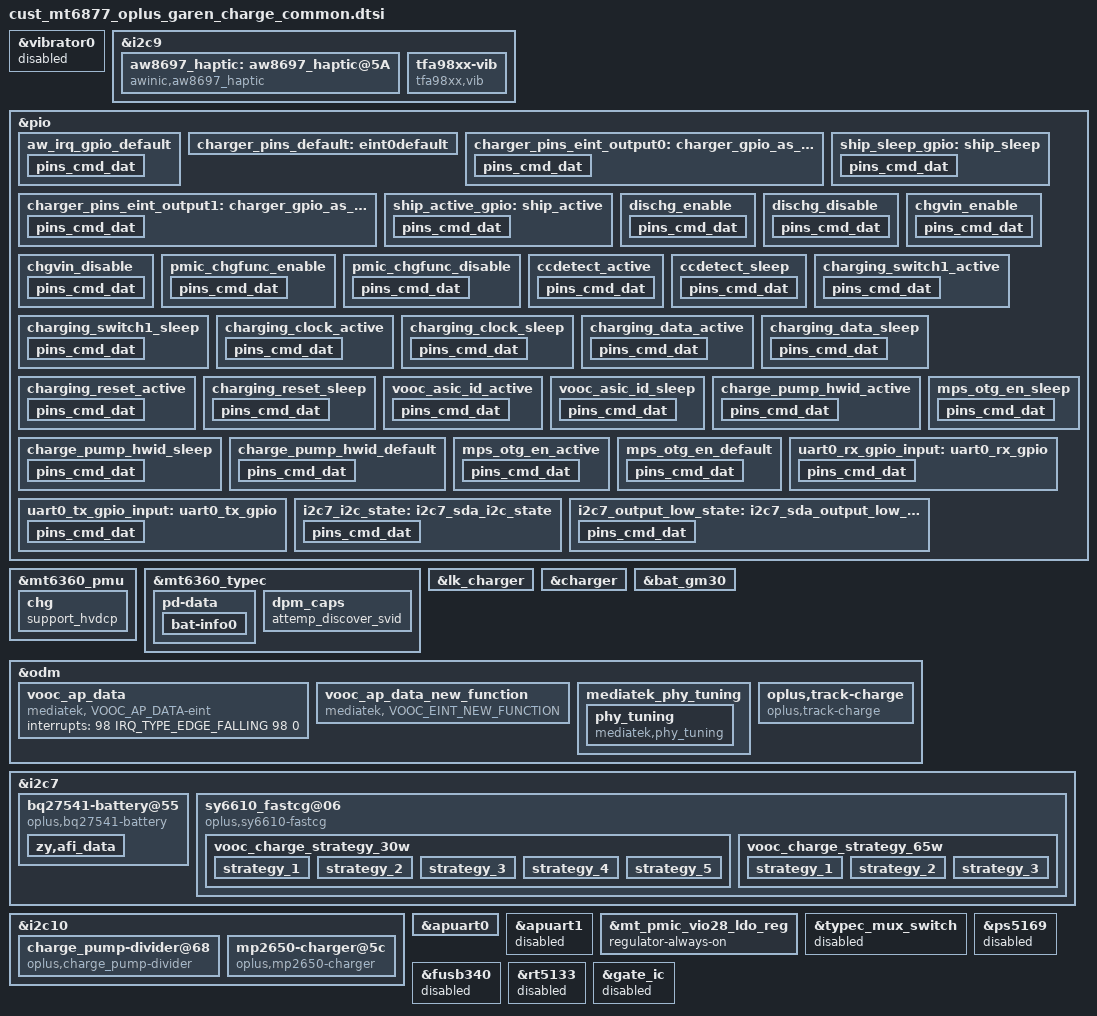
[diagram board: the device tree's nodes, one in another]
// SPDX-License-Identifier: GPL-2.0-only
/*
* Copyright (C) 2020-2021 Oplus. All rights reserved.
*/

//#ifdef OPLUS_FEATURE_CHG_BASIC
/*
 *
 * CPU:				--> MT6877
 * GPIO:
 * AP_AW			--> GPIO117(20181 EVT+20355 T0 NC)
 * LRA_RST			--> GPIO118(20181 EVT+20355 T0 I2S1_BCLK_SMPA)
 * AW_INT			--> GPIO3(20181 EVT+20355 T0 NC)
 * NDT_AW_SCL			--> GPIO147(SCL9)
 * NDT_AW_SDA			--> GPIO148(SDA9)
 *
 * MT6360_CHG_EN		--> GPIO111
 * PERIEN_CHG_ENB		--> GPIO142
 * MT6360_SCL			--> GPIO132(SCL5)
 * MT6360_SDA			--> GPIO133(SDA5)
 * EINT_SUBPMIC_IRQB		--> GPIO4
 * EINT_SUBPMIC_PD_IRQB		--> GPIO5
 *
 * GAUGE_SCL			--> GPIO134(SCL7)
 * GAUGE_SDA			--> GPIO135(SDA7)
 * AP_CLK			--> GPIO180
 * AP_DATA			--> GPIO181
 * SW_CTRL			--> GPIO24
 * USB_ON			--> GPIO25(20181 EVB-GPIO26 PU)
 * MCU_EN			--> GPIO33
 * ASIC_ID			--> GPIO34
 * ASIC_INT			--> GPIO9
 * SHIP_MODE_ON			--> GPIO108
 * UTXD0			--> GPIO178
 * URXD0			--> GPIO179
 *
 * MP2762_DA9313_SCL		--> GPIO191(SCL10)
 * MP2762_DA9313_SDA		--> GPIO192(SDA10)
 * MPS_OTG_EN			--> GPIO107
 * INPUT_PG			--> GPIO29
 * ChargerPump_ID		--> GPIO30
 * MAX77932_IRQB		--> GPIO10
 *
 * USB_ACC_INT			--> GPIO6
 * VBUS_SHORT			--> GPIO167(VIO28)
 *
 * AUXADC:
 * 0				--> AUX_IN0_NTC_AP
 * 1				--> AUX_IN1_NTC_PA1
 * 2				--> AUX_IN2_NTC_PA2
 * 3				--> CAM_FLASH_THER
 * 4				--> AUX_IN4_NTC_USB
 * 5				--> AUX_IN5_NTC_USB
 * 6				--> CHG_MOS_THERM
 * 7				--> MAIN_BOARD_ID
 * 8				--> SUB_BOARD_ID
 *******************************************
 * main pmic:			--> MT6365
 * charge pmic:			--> MT6360
 * charge ic:			--> MP2762GV
 * asic ic:
 * PD				--> SY6610(USE)
 * HZ				--> RT5125
 * PU				--> RK826
 * charge pump ic:
 * PD				--> DA9313/SD77313
 * PU				--> MAX77932/MAX77938
 * haptic ic:			--> AW8697/TFA9873
 * gauge ic:			--> sn28z719/SH366003
 * linear motor:		--> DM-LM0832-67
 */

&vibrator0 {
	status = "disabled";
};

&i2c9 {
	status = "okay";
	scl-gpio-id = <147>;
	sda-gpio-id = <148>;

	/* AWINIC AW8697 Haptic */
	aw8697_haptic: aw8697_haptic@5A {
		status = "okay";
		compatible = "awinic,aw8697_haptic";
		reg = <0x5A>;
		reset-gpio = <&pio 118 0x00>;
		irq-gpio = <&pio 3 0x00>;
		qcom,device_id = <832>;

		pinctrl-names = "default";
		pinctrl-0 = <&aw_irq_gpio_default>;
	};

	/*add for lk vib*/
	tfa98xx-vib {
		status = "okay";
		compatible = "tfa98xx,vib";
		reset-gpio =  <32>;
		interval_time = <14000>;
	};
};

&pio{
	aw_irq_gpio_default: aw_irq_gpio_default {
		pins_cmd_dat {
			pinmux = <PINMUX_GPIO3__FUNC_GPIO3>;
			input-enable;
			slew-rate = <0>;
			bias-pull-up;
		};
	};
};

&mt6360_pmu {
	mt6360,intr_gpio_num = <4>; /* direct defined GPIO num */
	mt6360,intr_gpio = <&pio 4 0x0>;
	disable_lpsd = <1>;

	chg {
		support_hvdcp;
	};
};

&mt6360_typec {
	mt6360pd,intr_gpio_num = <5>; /* direct defined GPIO num */
	mt6360pd,intr_gpio = <&pio 5 0x0>;
	mt-tcpc,role_def = <1>; /* 0: Unknown, 1: SNK only, 2: SRC only, 3: DRP, 4: Try.SRC, 5: Try.SNK */
	mt-tcpc,vconn_supply  = <1>; /* 0: Never, 1: Always, 2: EMarkOnly, 3: StartOnly */
	pd-data {
		pd,source-pdo-size = <1>;
		pd,source-pdo-data = <0x00019096>; /* Fixed5V1.5A */

		pd,sink-pdo-size = <2>;
		pd,sink-pdo-data = <0x000190c8 0x0001912c>; /* Fixed5V2A Fixed5V3A */

		pd,id-vdo-size = <3>;
		pd,id-vdo-data = <0xd10029cf 0x0 0x63600000>; /* No DP, host + device */

		bat,nr = <1>;
		bat-info0 {
			bat,vid = <0x29cf>;
			bat,pid = <0x6360>;
			bat,mfrs = "bat1";
			bat,design_cap = <16>; /*7.74V*2.15Ah=16.254Wh*/
		};
	};

	dpm_caps {
		attemp_discover_svid;
	};
};

&lk_charger{
	charger_by_buckboost;
	support_tuv_authentication;
};

&charger {
	io-channels = <&auxadc 4>,
		<&auxadc 5>,
		<&auxadc 6>;
	io-channel-names = "auxadc4-usb_temp_v_l",
		"auxadc5-usb_temp_v_r",
		"auxadc3-chargeric_temp";

	pinctrl-names = "default", "charger_gpio_as_output_low", "charger_gpio_as_output_high", "ship_sleep", "ship_active",
		"dischg_enable", "dischg_disable", "chgvin_enable", "chgvin_disable", "pmic_chgfunc_enable", "pmic_chgfunc_disable",
		"ccdetect_active","ccdetect_sleep";
	pinctrl-0 = <&charger_pins_default>;
	pinctrl-1 = <&charger_pins_eint_output0>;
	pinctrl-2 = <&charger_pins_eint_output1>;
	pinctrl-3 = <&ship_sleep_gpio>;
	pinctrl-4 = <&ship_active_gpio>;
	pinctrl-5 = <&dischg_enable>;
	pinctrl-6 = <&dischg_disable>;
	pinctrl-7 = <&chgvin_enable>;
	pinctrl-8 = <&chgvin_disable>;
	pinctrl-9 = <&pmic_chgfunc_enable>;
	pinctrl-10 = <&pmic_chgfunc_disable>;
	pinctrl-11 = <&ccdetect_active>;
	pinctrl-12 = <&ccdetect_sleep>;

	qcom,hv_flashled_support;
	qcom,chargerid_support;
	qcom,smart_charging_screenoff;
	qcom,usbtemp_batttemp_gap = <18>;
	qcom,input_current_charger_ma = <2000>;
	qcom,pd_input_current_charger_ma = <2000>;
	qcom,qc_input_current_charger_ma = <2000>;
	qcom,input_current_usb_ma = <500>;

	qcom,input_current_led_ma = <1200>;
	qcom,input_current_led_ma_high = <1200>;
	qcom,input_current_led_ma_warm = <1500>;
	qcom,input_current_led_ma_normal = <2000>;
	qcom,led_warm_bat_decidegc = <350>;
	qcom,led_high_bat_decidegc = <370>;

	qcom,input_current_camera_ma = <1200>;
	qcom,input_current_cdp_ma = <1500>;

	qcom,input_current_vooc_led_ma_high = <1200>;
	qcom,input_current_vooc_led_ma_warm = <1800>;
	qcom,input_current_vooc_led_ma_normal = <3600>;
	qcom,input_current_vooc_ma_normal = <3600>;
	qcom,vooc_temp_bat_normal_decidegc = <350>;
	qcom,input_current_vooc_ma_warm = <3200>;
	qcom,vooc_temp_bat_warm_decidegc = <370>;
	qcom,input_current_vooc_ma_high = <2200>;
	qcom,vooc_temp_bat_hot_decidegc = <440>;

	qcom,charger_current_vooc_ma_normal = <1800>;

	qcom,chg_ctrl_by_calling;
	qcom,input_current_calling_ma = <1500>;

	qcom,overtemp_bat_decidegc = <350>;
	qcom,iterm_disabled = <0>;
	sw_full_count = <25>;
	qcom,iterm_ma = <115>;
	qcom,recharge-mv = <100>;
	qcom,batt_capacity_mah = <4300>;/*typical capacity*/

	qcom,removed_bat_decidegc = <190>;  /*<-19C*/

	qcom,cold_bat_decidegc = <20>;  /*-2C~0C*/
	qcom,temp_cold_vfloat_mv = <3980>;
	qcom,temp_cold_fastchg_current_ma = <300>;

	qcom,little_cold_bat_decidegc = <0>;    /*0C~5C*/
	qcom,temp_little_cold_vfloat_mv = <4435>;
	qcom,temp_little_cold_fastchg_current_ma_high = <1100>;
	qcom,temp_little_cold_fastchg_current_ma_low = <1100>;
	qcom,temp_little_cold_fastchg_current_ma = <1100>;
	qcom,pd_temp_little_cold_fastchg_current_ma_high = <1950>;
	qcom,pd_temp_little_cold_fastchg_current_ma_low = <1350>;
	qcom,qc_temp_little_cold_fastchg_current_ma_high = <1950>;
	qcom,qc_temp_little_cold_fastchg_current_ma_low = <1350>;

	qcom,cool_bat_decidegc = <50>;  /*5C~12C*/
	qcom,temp_cool_vfloat_mv = <4435>;
	qcom,temp_cool_fastchg_current_ma_high = <1100>;
	qcom,temp_cool_fastchg_current_ma_low = <1100>;
	qcom,pd_temp_cool_fastchg_current_ma_high = <2000>;
	qcom,pd_temp_cool_fastchg_current_ma_low = <2000>;
	qcom,qc_temp_cool_fastchg_current_ma_high = <2000>;
	qcom,qc_temp_cool_fastchg_current_ma_low = <2000>;

	qcom,little_cool_bat_decidegc = <120>;  /*12C~16C*/
	qcom,temp_little_cool_vfloat_mv = <4435>;
	qcom,temp_little_cool_fastchg_current_ma = <1100>;
	qcom,pd_temp_little_cool_fastchg_current_ma = <2000>;
	qcom,qc_temp_little_cool_fastchg_current_ma = <2000>;

	qcom,normal_bat_decidegc = <160>;       /*16C~45C*/
	qcom,temp_normal_vfloat_mv = <4435>;
	qcom,temp_normal_fastchg_current_ma = <1100>;
	qcom,pd_temp_normal_fastchg_current_ma = <2000>;
	qcom,qc_temp_normal_fastchg_current_ma = <2000>;

	qcom,warm_bat_decidegc = <450>;         /*45C~53C*/ /*8pin Bat Vooc project need add 3 degree C*/
	qcom,temp_warm_vfloat_mv = <4130>;
	qcom,temp_warm_fastchg_current_ma = <550>;
	qcom,pd_temp_warm_fastchg_current_ma = <550>;
	qcom,qc_temp_warm_fastchg_current_ma = <550>;
	qcom,temp_warm_fastchg_current_ma_led_on = <250>;

	qcom,hot_bat_decidegc = <530>;

	qcom,non_standard_vfloat_mv = <3980>;
	qcom,non_standard_fastchg_current_ma = <512>;

	qcom,short_c_bat_cv_mv = <4330>;
	qcom,short_c_bat_vfloat_mv = <3800>;
	qcom,short_c_bat_fastchg_current_ma = <512>;

	qcom,cold_vfloat_sw_limit = <3930>;
	qcom,little_cold_vfloat_sw_limit = <4385>;
	qcom,cool_vfloat_sw_limit = <4385>;
	qcom,little_cool_vfloat_sw_limit = <4385>;
	qcom,normal_vfloat_sw_limit = <4385>;
	qcom,warm_vfloat_sw_limit = <4080>;
	qcom,non_standard_vfloat_sw_limit = <3930>;
	qcom,short_c_bat_vfloat_sw_limit = <3750>;

	qcom,max_chg_time_sec = <61200>;
	qcom,charger_hv_thr = <9900>;
	qcom,charger_recv_thr = <9500>;
	qcom,charger_lv_thr = <3400>;
	qcom,vbatt_full_thr = <4435>;
	qcom,vbatt_hv_thr = <4600>;

	qcom,vfloat_step_mv = <8>;
	qcom,cold_vfloat_over_sw_limit = <3990>;
	qcom,little_cold_vfloat_over_sw_limit = <4445>;
	qcom,cool_vfloat_over_sw_limit = <4445>;
	qcom,little_cool_vfloat_over_sw_limit = <4445>;
	qcom,normal_vfloat_over_sw_limit = <4445>;
	qcom,warm_vfloat_over_sw_limit = <4140>;
	qcom,non_standard_vfloat_over_sw_limit = <3990>;

	qcom,vbatt_power_off = <3300>;
	qcom,vbatt_soc_1 = <3310>;
	qcom,vooc_project = <3>;
	qcom,vbatt_num = <2>;
	qcom,new_ui_warning_support;
	qcom,ffc_support;
	qcom,dual_ffc;
	recharge_after_full;

	qcom,normal_vterm_hw_inc = <18>;
	qcom,non_normal_vterm_hw_inc = <18>;

	qcom,ff1_normal_fastchg_ma = <550>;
	qcom,ff1_warm_fastchg_ma = <550>;

	qcom,ffc2_normal_fastchg_ma = <350>;/*12C~35c*/
	qcom,ffc2_temp_warm_decidegc = <350>;
	qcom,ffc2_warm_fastchg_ma = <350>;/*35C~40c*/
	qcom,ffc2_temp_high_decidegc = <400>;
	qcom,ffc2_temp_low_decidegc = <120>;

	qcom,ff1_exit_step_ma = <150>;
	qcom,ff1_warm_exit_step_ma = <150>;
	qcom,ffc2_exit_step_ma = <150>;
	qcom,ffc2_warm_exit_step_ma = <150>;

	qcom,ffc_normal_vfloat_sw_limit = <4445>;
	qcom,ffc_temp_normal_vfloat_mv = <4500>;
	qcom,ffc_normal_vfloat_over_sw_limit = <4500>;
	qcom,ffc_warm_vfloat_sw_limit = <4445>;
	qcom,ffc_temp_warm_vfloat_mv = <4500>;
	qcom,ffc_warm_vfloat_over_sw_limit = <4500>;

	qcom,ffc2_normal_vfloat_sw_limit = <4440>;
	qcom,ffc2_temp_normal_vfloat_mv = <4500>;
	qcom,ffc2_normal_vfloat_over_sw_limit = <4500>;
	qcom,ffc2_warm_vfloat_sw_limit = <4435>;
	qcom,ffc2_temp_warm_vfloat_mv = <4500>;
	qcom,ffc2_warm_vfloat_over_sw_limit = <4500>;

	qcom,default_iterm_ma = <115>;
	qcom,default_temp_normal_fastchg_current_ma = <1100>;
	qcom,default_normal_vfloat_sw_limit = <4385>;
	qcom,default_temp_normal_vfloat_mv = <4435>;
	qcom,default_normal_vfloat_over_sw_limit = <4445>;

	qcom,default_temp_little_cool_fastchg_current_ma = <1100>;
	qcom,default_little_cool_vfloat_sw_limit = <4385>;
	qcom,default_temp_little_cool_vfloat_mv = <4435>;
	qcom,default_little_cool_vfloat_over_sw_limit = <4445>;

	qcom,vooc_show_ui_soc_decimal;
	qcom,ui_soc_decimal_speedmin = <20>;//2A
	qcom,check_batt_full_by_sw;
	qcom,external_gauge;
	qcom,chg_ctrl_by_lcd;
	qcom,chg_ctrl_by_vooc;
	qcom,chg_ctrl_by_camera;
	qcom,support_ntc_01c_precision;
	qcom,sw_vfloat_over_protect_enable;

	qcom,support_abnormal_adapter;

	//for PD9V or QC9V
	qcom,vbatt_pdqc_to_5v_thr = <4100>;
	qcom,vbatt_pdqc_to_9v_thr = <4000>;

	oplus,aging_ffc_version = <1>;

	//GPIO config:
	qcom,chargerid_switch-gpio = <&pio 25 0x00>;
	qcom,ship-gpio = <&pio 108 0x00>;
	qcom,dischg-gpio = <&pio 167 0x00>;
	qcom,ccdetect-gpio = <&pio 6 0x00>;

	qcom,chgvin = <&pio 111 0x00>;
	qcom,pmic_chgfunc = <&pio 142 0x00>;
};

&pio {
	charger_pins_default: eint0default {
	};

	charger_pins_eint_output0: charger_gpio_as_output_low {
		pins_cmd_dat {
			pinmux = <PINMUX_GPIO25__FUNC_GPIO25>;
			slew-rate = <1>;
			output-low;
		};
	};

	charger_pins_eint_output1: charger_gpio_as_output_high {
		pins_cmd_dat {
			pinmux = <PINMUX_GPIO25__FUNC_GPIO25>;
			slew-rate = <1>;
			output-high;
		};
	};

	ship_sleep_gpio: ship_sleep {
		pins_cmd_dat {
			pinmux = <PINMUX_GPIO108__FUNC_GPIO108>;
			slew-rate = <1>;
			output-low;
		};
	};

	ship_active_gpio: ship_active {
		pins_cmd_dat {
			pinmux = <PINMUX_GPIO108__FUNC_GPIO108>;
			slew-rate = <1>;
			output-high;
		};
	};

	dischg_enable: dischg_enable {
		pins_cmd_dat {
			pinmux = <PINMUX_GPIO167__FUNC_GPIO167>;
			slew-rate = <1>;
			output-high;
		};
	};

	dischg_disable: dischg_disable {
		pins_cmd_dat {
			pinmux = <PINMUX_GPIO167__FUNC_GPIO167>;
			slew-rate = <1>;
			output-low;
		};
	};

	chgvin_enable: chgvin_enable {
		pins_cmd_dat {
			pinmux = <PINMUX_GPIO111__FUNC_GPIO111>;
			slew-rate = <1>;
			output-low;
		};
	};

	chgvin_disable: chgvin_disable {
		pins_cmd_dat {
			pinmux = <PINMUX_GPIO111__FUNC_GPIO111>;
			slew-rate = <1>;
			output-high;
		};
	};

	pmic_chgfunc_enable: pmic_chgfunc_enable {
		pins_cmd_dat {
			pinmux = <PINMUX_GPIO142__FUNC_GPIO142>;
			slew-rate = <1>;
			output-low;
		};
	};

	pmic_chgfunc_disable: pmic_chgfunc_disable {
		pins_cmd_dat {
			pinmux = <PINMUX_GPIO142__FUNC_GPIO142>;
			slew-rate = <1>;
			output-high;
		};
	};

	ccdetect_active: ccdetect_active {
		pins_cmd_dat {
			pinmux = <PINMUX_GPIO6__FUNC_GPIO6>;
			input-enable;
			slew-rate = <0>;
			bias-disable;
		};
	};

	ccdetect_sleep: ccdetect_sleep {
		pins_cmd_dat {
			pinmux = <PINMUX_GPIO6__FUNC_GPIO6>;
			input-enable;
			slew-rate = <0>;
			bias-disable;
		};
	};
};

&bat_gm30 {
	FUELGAGUE_APPLY = <(0)>;
	DISABLE_MTKBATTERY = <(1)>;
};

&odm {
	vooc_ap_data:vooc_ap_data {
		compatible = "mediatek, VOOC_AP_DATA-eint";
		interrupts = <98 IRQ_TYPE_EDGE_FALLING 98 0>;
	};

	vooc_ap_data_new_function:vooc_ap_data_new_function {
		compatible = "mediatek, VOOC_EINT_NEW_FUNCTION";
	};
};

&i2c7 {
	status = "okay";
	clock-frequency = <100000>;//100K
	scl-gpio-id = <134>;
	sda-gpio-id = <135>;

	bq27541-battery@55 {
		status = "okay";
		compatible = "oplus,bq27541-battery";
		reg = <0x55>;
		qcom,modify-soc-smooth;
		qcom,modify-soc-calibration;
		qcom,batt_bq28z610;
		qcom,sha1_key_index = <1>;
		//qcom,bq28z610_need_balancing;
		zy,afi_data{
			battery,name = "BLP863";
			qmax_min = <1696>;
			qmax_max = <2438>;
			static_df_checksum_3e = [79 C0];			//len 2
			static_df_checksum_60 = [0A 06];			//len 2
			afi_buf_num = <7>;
			afi_buf_0 = [
				11 D0 11 17 11 D0 11 17 11 D0 11 17 11 D0 11 17
				01 0A 8C 0A 0C 1C 21 34 02 FF CE 02 EC 78 02 FF
				CE 05 C2 0A C2 0A 72 A3 0A 0C D1 02 0C 9F 0D 03
				02 0C D1 0A 79 02 0A AB 09 E3 02 0A 15 07 D0 07
				08 07 08 00 02 09 C4 07 D0 D2 F0 00 02 03 E8 05
				11 EE 05 0E 74 00 0A 01 F4 0A 07 08 0E 74 00 0A
				01 F4 0A 00 0A 05 FF F6 05 0A 0A AB 0B 23 0B 73
				0B A5 0B D7 0C D1 00 0A 00 58 00 2C 11 5D 00 84
				01 60 01 08 11 5D 07 BC 0F A4 0B B0 11 5D 09 CC
				11 88 0D C0 11 5D 03 F4 07 BC 05 D8 09 C4 0D 48
				0E D8 0F A0 00 01 01 2C 01 2C 01 2C 01 2C 00 4B
				03 84 28 01 65 01 6B 03 00 00 46 50 50 00 30 00
				96 00 AF 08 48 06 68 1E 3C 5A
				];
			afi_buf_1 = [
				64 63 64 61 00 01 01 02 05 21 1C 00 A2 40 05 57
				20 00 00 03 00 00 0A F0 0A 28 14 0A 14 10 E0 64
				07 D0 00 03 0F 00 14 04 19 C8 00
				];
			afi_buf_2 = [
				AA 21 10 03 EF 05 AA 07 85 09 24 0B 80 0D 40 0F
				3C 11 3E 13 39 15 1B 17 B6 19 0C 3B 3C 7D F8 B5
				00 33 22 4F 24 2B 26 E9 28 C7 2A 26 2C A3 2E 03
				30 7D 32 7E 34 78 36 99 38 EC 1A 5E 5C 24 08 70
				08 77 33
				];
			afi_buf_3 = [
				11 38 11 38 01 2C FF 38 FE 20 FE D5 FC 18 00 6A
				00 32 00 32
				];
			afi_buf_4 = [79 C0];
			afi_buf_5 = [
				FF 21 10 03 EF 05 AA 07 85 09 24 0B 80 0D 40 0F
				3C 11 3E 13 39 15 1B 17 B6 19 0C 1B C6 5D CB E0
				00 33 22 4F 24 2B 26 E9 28 C7 2A 26 2C A3 2E 03
				30 7D 32 7E 34 78 36 99 38 0A 1A DB 5C 57 01 01
				00 00 00 00 00 14 00 0F 00 46 00 3C 00 3C 01 3C
				FF F6 FE 0C 32
				];
			afi_buf_6 = [
				E4 AD 20 2F 26 0C 24 E2 2A CB 08 B4 0E F6 0C 57
				12 25 10 43 16 59 14 9F 1A DD 18 3A FD A0 FF 25
				C1 F7 C3 F1 C5 CB C7 4C C9 CE CB EE CD 8E CF EE
				D1 31 F3 AD F5 08 F7 4B F9 02 FB 21 FD E5 FF 28
				81 14 83 D0 85 B4 87 08 89 87 8B 05 8D 87 EF FA
				31 E4 CD 28 CB CD C9 45 C7 89 C5 3E C3 F0 C1 B0
				DF A1 DD 29 DB 88 D9 A9 D7 39 D5 33 D3 B7 B1 27
				8F FB 8D 47 AB FA 89 78 78 CC 7A 42 5C 7D 5E 70
				A0 4E A2 79 A4 49 79 52 57 57 15 E7 D3 FE D1 EA
				CF 12 CD FB 8B 0F C9 4C E7 F5 C5 36 41 42 63 BE
				1F 7A 7D 13 7B BF 59 27 57 AA 75 3F 53 6C 71 10
				4F 95 4D 77 4B 70 49 F2 47 D7 45 00 9C FE BE 66
				1F A0 1D 23 1B 67 19 40 17 66 15 2C 13 41 11 CF
				6F CD 6D E9 6B A9 69 8F 07 19 05 94 23 56 FE 5A
				E0 E1 E2 20 E4 26 E6 FE C8 6C 8A EB AC AC ED EB
				90 10 B3 F3 78 F5 B6 D4 E1 38 01 3A F0 DD EC FF
				8C 21 62 A3 A4 A1 CE 07 8A 05 4B 28 09 81 4E 04
				10 51 12 13 75 02 36 92 5E 5F 5B 5B 7C 5D 5F 5E
				61 67 E3 83 A4 CA 86 A5 28 30 6A BC EC 2D 2E AD
				54 31 2B 73 E9 16 BA 76 58 69 DC FB 93 3D 3E DE
				B0 41 A3 A3 3C 45 46 47 48 49 A7 2A 05 4D E2 6E
				19 51 B7 73 7D 55 B7 57 70 59 BF BA 14 5D 5E 5F
				60 61 62 63 64 65 C3 86 21 69 4B AA A4 6D 6E 6F
				70 71 72 73 74 75 76 77 78 79 7A 7B 7C 7D 7E 7F
				80 7E 02 83 E4 C5 C6 87 C8 89 8A 8B 8C 8D 4F 8D
				90 9E FC 99 D4 74 B6 85 98 80 9A 82 1C 9D 5D FF
				A0 2D A2 FC 04 29 A6 BE C8 89 61 AB F3 2F 8E BD
				15 3D 12 F8 14 B5 B6 B7 0C B2 0C E4 0A 5F 01 2C
				];
		};
	};

	sy6610_fastcg@06{
		status = "okay";
		compatible = "oplus,sy6610-fastcg";
		reg = <0x06>;
		qcom,support_vooc_by_normal_charger_path;
		qcom,vooc_fw_update_newmethod;
		qcom,fw_update_on_chargering_reboot;
		qcom,vooc-fw-type = <3>;
		qcom,vooc_reply_mcu_bits = <7>;
		#include "mediatek/fastchg_fw/fw_svooc_10v6.3a_4.45v_oplus20181_op10_7b.dtsi"
		qcom,vooc-low-temp = <0>;
		qcom,vooc-high-temp = <430>;
		qcom,vooc-low-soc = <1>;
		qcom,vooc-high-soc = <90>;
		qcom,vooc-little-cool-temp = <160>;
		qcom,vooc-cool-temp = <120>;
		qcom,vooc-little-cool-to-normal-temp = <180>;
		qcom,vooc-normal-to-little-cool-current = <0x05>;//5A

		qcom,vooc_cool_bat_volt = <3450>;
		qcom,vooc_little_cool_bat_volt = <3400>;
		qcom,vooc_normal_bat_volt = <3350>;
		qcom,vooc_warm_bat_volt = <3300>;

		qcom,vooc_cool_bat_suspend_volt = <3450>;
		qcom,vooc_little_cool_bat_suspend_volt = <3400>;
		qcom,vooc_normal_bat_suspend_volt = <3350>;
		qcom,vooc_warm_bat_suspend_volt = <3300>;

		qcom,vooc_multistep_adjust_current_support;
		qcom,vooc_multistep_initial_batt_temp = <1000>;
		qcom,vooc_strategy_normal_current = <0x0c>;
		qcom,vooc_batt_over_high_temp = <440>;
		qcom,vooc_batt_over_low_temp = <45>;
		qcom,vooc_over_high_or_low_current = <0x0>;

		qcom,vooc_strategy1_batt_high_temp0 = <400>;
		qcom,vooc_strategy1_batt_high_temp1 = <420>;
		qcom,vooc_strategy1_batt_high_temp2 = <430>;
		qcom,vooc_strategy1_batt_low_temp2 = <420>;
		qcom,vooc_strategy1_batt_low_temp1 = <410>;
		qcom,vooc_strategy1_batt_low_temp0 = <390>;

		qcom,vooc_strategy1_high_current0 = <0x09>;  // 5A
		qcom,vooc_strategy1_high_current1 = <0x07>;  // 4A
		qcom,vooc_strategy1_high_current2 = <0x05>;  // 3A
		qcom,vooc_strategy1_low_current2 = <0x07>;   // 4A
		qcom,vooc_strategy1_low_current1 = <0x09>;   // 5A
		qcom,vooc_strategy1_low_current0 = <0x0c>;   // 0x0c

		qcom,vooc_strategy2_batt_up_temp1 = <375>;
		qcom,vooc_strategy2_batt_up_down_temp2 = <380>;
		qcom,vooc_strategy2_batt_up_temp3 = <390>;
		qcom,vooc_strategy2_batt_up_down_temp4 = <400>;
		qcom,vooc_strategy2_batt_up_temp5 = <410>;
		qcom,vooc_strategy2_batt_up_temp6 = <415>;
		qcom,vooc_strategy2_high0_current = <0x09>;
		qcom,vooc_strategy2_high1_current = <0x07>;
		qcom,vooc_strategy2_high2_current = <0x05>;
		qcom,vooc_strategy2_high3_current = <0x03>;

		qcom,abnormal_adapter_current = <0x00 0x00 0x09 0x09 0x07 0x07 0x05 0x05 0x03 0x03>;

		qcom,vooc_current_lvl = <1000
									1500
									2000
									2500
									3000
									3500
									4000
									4500
									5000
									5500
									6000
									6500
									7000
									7500
									8000
									8500
									9000
									9500
									10000
									10500
									11000
									11500
									12000
									12500>;
		pinctrl-names = "switch1_act_switch2_act", "switch1_sleep_switch2_sleep",
						"switch1_act_switch3_act", "switch1_sleep_switch3_sleep",
						"switch1_act_switch2_sleep", "switch1_sleep_switch2_act",
						"clock_active","clock_sleep",
						"data_active","data_sleep",
						"reset_active","reset_sleep",
						"vooc_asic_id_active","vooc_asic_id_sleep";
		pinctrl-0 = <&charging_switch1_active>;
		pinctrl-1 = <&charging_switch1_sleep>;
		pinctrl-2 = <&charging_switch1_active>;
		pinctrl-3 = <&charging_switch1_sleep>;
		pinctrl-4 = <&charging_switch1_active>;
		pinctrl-5 = <&charging_switch1_sleep>;
		pinctrl-6 = <&charging_clock_active>;
		pinctrl-7 = <&charging_clock_sleep>;
		pinctrl-8 = <&charging_data_active>;
		pinctrl-9 = <&charging_data_sleep>;
		pinctrl-10 = <&charging_reset_active>;
		pinctrl-11 = <&charging_reset_sleep>;
		pinctrl-12 = <&vooc_asic_id_active>;
		pinctrl-13 = <&vooc_asic_id_sleep>;

		qcom,charging_switch1-gpio 		= <&pio 24 0x00>;
		qcom,charging_reset-gpio 		= <&pio 33 0x00>;
		qcom,charging_clock-gpio 		= <&pio 180 0x00>;
		qcom,charging_data-gpio 		= <&pio 181 0x00>;
		qcom,vooc_asic_id-gpio			= <&pio 34 0x00>;

		qcom,vooc-max-input-volt-support = <10000>;     //10V
		qcom,vooc-max-input-current-support = <6500>;   //6A
		vooc_charge_strategy_30w {
			strategy_1 {
				capacity_range = <0 75>;
				temp_range = <120 160>;
				input_current = <4000 4450 0
						3000 4470 0
						2000 4480 0>;
				};
			strategy_2 {
				capacity_range = <0 75>;
				temp_range = <160 410>;
				input_current = <6000 4200 900
						5000 4200 0
						4500 4450 0
						4000 4450 0
						3000 4470 0
						2000 4480 0>;
			};
			strategy_3 {
				capacity_range = <0 75>;
				temp_range = <410 420>;
				input_current = <4000 4470 0
						2000 4480 0>;
			};
			strategy_4 {
				capacity_range = <0 75>;
				temp_range = <420 425>;
				input_current = <4000 4480 0>;
			};
			strategy_5 {
				capacity_range = <0 75>;
				temp_range = <425 435>;
				input_current = <3000 4480 0>;
			};
		};

		vooc_charge_strategy_65w {
			strategy_1 {
				capacity_range = <0 50>;
				temp_range = <120 160>;
				input_current = <6000 4200 0
						4000 4454 0
						2000 4494 0
						1500 4500 0>;
			};
			strategy_2 {
				capacity_range = <0 50>;
				temp_range = <160 370>;
				input_current = <6500 4200 0
						6000 4250 300
						5500 4300 400
						4500 4454 780
						3500 4454 0
						2000 4494 0
						1500 4500 0>;
			};
			strategy_3 {
				capacity_range = <0 90>;
				temp_range = <370 430>;
				input_current = <6500 4200 0
						6000 4250 300
						5500 4300 400
						4500 4454 780
						3500 4454 0
						2000 4494 0
						1600 4500 0>;
			};
		};
	};
};

&pio {
	charging_switch1_active: charging_switch1_active {
		pins_cmd_dat {
			pinmux = <PINMUX_GPIO24__FUNC_GPIO24>;
			slew-rate = <1>;
			output-high;
		};
	};

	charging_switch1_sleep: charging_switch1_sleep {
		pins_cmd_dat {
			pinmux = <PINMUX_GPIO24__FUNC_GPIO24>;
			slew-rate = <1>;
			output-low;
		};
	};

	charging_clock_active: charging_clock_active {
		pins_cmd_dat {
			pinmux = <PINMUX_GPIO180__FUNC_GPIO180>;
			slew-rate = <0>;
			bias-pull-up;
		};
	};

	charging_clock_sleep: charging_clock_sleep {
		pins_cmd_dat {
			pinmux = <PINMUX_GPIO180__FUNC_GPIO180>;
			slew-rate = <0>;
			bias-pull-down;
		};
	};

	charging_data_active: charging_data_active {
		pins_cmd_dat {
			pinmux = <PINMUX_GPIO181__FUNC_GPIO181>;
			slew-rate = <0>;
			bias-pull-down;
		};
	};

	charging_data_sleep: charging_data_sleep {
		pins_cmd_dat {
			pinmux = <PINMUX_GPIO181__FUNC_GPIO181>;
			slew-rate = <0>;
			bias-pull-down;
		};
	};

	charging_reset_active: charging_reset_active {
		pins_cmd_dat {
			pinmux = <PINMUX_GPIO33__FUNC_GPIO33>;
			slew-rate = <1>;
			bias-disable;
		};
	};

	charging_reset_sleep: charging_reset_sleep {
		pins_cmd_dat {
			pinmux = <PINMUX_GPIO33__FUNC_GPIO33>;
			slew-rate = <1>;
			bias-disable;
		};
	};

	vooc_asic_id_active: vooc_asic_id_active {
		pins_cmd_dat {
			pinmux = <PINMUX_GPIO34__FUNC_GPIO34>;
			input-enable;
			slew-rate = <0>;
			bias-pull-up = <MTK_PUPD_SET_R1R0_10>;//50K
		};
	};

	vooc_asic_id_sleep: vooc_asic_id_sleep {
		pins_cmd_dat {
			pinmux = <PINMUX_GPIO34__FUNC_GPIO34>;
			input-enable;
			slew-rate = <0>;
			bias-pull-down = <MTK_PUPD_SET_R1R0_10>;//50K
		};
	};
};

&i2c10 {
	status = "okay";
	clock-frequency = <100000>;//100K
	scl-gpio-id = <191>;
	sda-gpio-id = <192>;

	charge_pump-divider@68 {
		status = "okay";
		compatible = "oplus,charge_pump-divider";
		reg = <0x68>;
		oplus,charge_pump-hwid-gpio = <&pio 30 0>;
		pinctrl-names = "charge_pump_hwid_active", "charge_pump_hwid_sleep", "charge_pump_hwid_default";
		pinctrl-0 = <&charge_pump_hwid_active>;
		pinctrl-1 = <&charge_pump_hwid_sleep>;
		pinctrl-2 = <&charge_pump_hwid_default>;
	};

	mp2650-charger@5c {
		status = "okay";
		compatible = "oplus,mp2650-charger";
		reg = <0x5c>;

		qcom,mps_otg_en-gpio = <&pio 107 0x00>;
		pinctrl-names = "mps_otg_en_active", "mps_otg_en_sleep", "mps_otg_en_default";
		pinctrl-0 = <&mps_otg_en_active>;
		pinctrl-1 = <&mps_otg_en_sleep>;
		pinctrl-2 = <&mps_otg_en_default>;
	};
};

&pio {
	charge_pump_hwid_active: charge_pump_hwid_active {
		pins_cmd_dat {
			pinmux = <PINMUX_GPIO30__FUNC_GPIO30>;
			input-enable;
			slew-rate = <0>;
			bias-pull-up = <MTK_PUPD_SET_R1R0_10>;//50K
		};
	};

	charge_pump_hwid_sleep: charge_pump_hwid_sleep {
		pins_cmd_dat {
			pinmux = <PINMUX_GPIO30__FUNC_GPIO30>;
			input-enable;
			slew-rate = <0>;
			bias-pull-down = <MTK_PUPD_SET_R1R0_10>;//50K
		};
	};

	charge_pump_hwid_default: charge_pump_hwid_default {
		pins_cmd_dat {
			pinmux = <PINMUX_GPIO30__FUNC_GPIO30>;
			input-enable;
			slew-rate = <0>;
			bias-disable;
		};
	};

	mps_otg_en_active: mps_otg_en_active {
		pins_cmd_dat {
			pinmux = <PINMUX_GPIO107__FUNC_GPIO107>;
			slew-rate = <1>;
			bias-pull-up;
		};
	};

	mps_otg_en_sleep: mps_otg_en_sleep {
		pins_cmd_dat {
			pinmux = <PINMUX_GPIO107__FUNC_GPIO107>;
			slew-rate = <1>;
			bias-pull-down;
		};
	};

	mps_otg_en_default: mps_otg_en_default {
		pins_cmd_dat {
			pinmux = <PINMUX_GPIO107__FUNC_GPIO107>;
			slew-rate = <1>;
			bias-pull-down;
		};
	};
};

&apuart0 {
	pinctrl-names = "uart0_rx_gpio",
			"uart0_tx_gpio";
	pinctrl-0 = <&uart0_rx_gpio_input>;
	pinctrl-1 = <&uart0_tx_gpio_input>;
	status = "okay";
};

&apuart1 {
	status = "disabled";
};

&pio {
	uart0_rx_gpio_input:uart0_rx_gpio {
		pins_cmd_dat {
			pinmux = <PINMUX_GPIO179__FUNC_GPIO179>;
			input-enable;
			slew-rate = <0>;
			bias-disable;
		};
	};

	uart0_tx_gpio_input:uart0_tx_gpio {
		pins_cmd_dat {
			pinmux = <PINMUX_GPIO178__FUNC_GPIO178>;
			input-enable;
			slew-rate = <0>;
			bias-disable;
		};
	};
};

&mt_pmic_vio28_ldo_reg {
	regulator-always-on;//for VBUS_SHORT
};

&typec_mux_switch {
	status = "disabled";
};

&ps5169{
	status = "disabled";
};

&fusb340 {
	status = "disabled";
};

&odm {
	mediatek_phy_tuning: mediatek_phy_tuning {
		phy_tuning {
			compatible = "mediatek,phy_tuning";
			eye-vrt = <6>;
			eye-term = <6>;
			eye-rev6 = <3>;
			u2_discth = <0xc>;
			host-eye-vrt = <6>;
			host-eye-term = <6>;
			host-eye-rev6 = <3>;
			host_u2_discth = <0xc>;
		};
	};

	oplus,track-charge {
		compatible = "oplus,track-charge";
		track,fast_chg_break_t_thd = <1000>;
		track,general_chg_break_t_thd = <200>;
		track,voocphy_type = <4>;
		track,wired_max_power = <65000>;
		track,wired_fast_chg_scheme = <1>;
	};
};

&i2c7 {
	pinctrl-names = "i2c-state", "output-low-state";
	pinctrl-0 = <&i2c7_i2c_state>;
	pinctrl-1 = <&i2c7_output_low_state>;
};

&pio {
	i2c7_i2c_state: i2c7_sda_i2c_state {
		pins_cmd_dat {
			pinmux = <PINMUX_GPIO135__FUNC_SDA7>;
			slew-rate = <0>;
			bias-disable;
		};
	};
	i2c7_output_low_state: i2c7_sda_output_low_state {
		pins_cmd_dat {
			pinmux = <PINMUX_GPIO135__FUNC_GPIO135>;
			slew-rate = <1>;
			output-low;
		};
	};
};

&rt5133 {
	status = "disabled";
};

&gate_ic {
	status = "disabled";
};

//#endif /*OPLUS_FEATURE_CHG_BASIC*/
